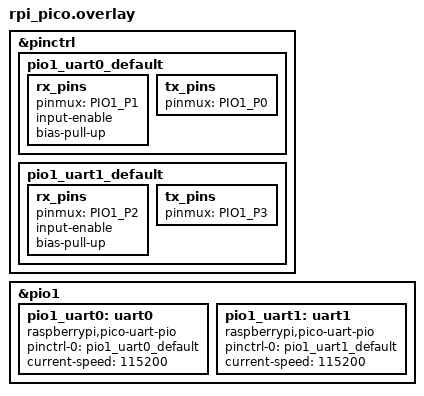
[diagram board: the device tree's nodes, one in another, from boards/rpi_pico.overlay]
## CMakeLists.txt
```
cmake_minimum_required(VERSION 3.15.0)
find_package(Zephyr REQUIRED HINTS $ENV{ZEPHYR_BASE})
project(pio_shell_uart)

target_sources(app PRIVATE src/main.c)
```

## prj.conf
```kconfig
CONFIG_LOG=y
CONFIG_SHELL=y
CONFIG_SERIAL=y
CONFIG_UART_INTERRUPT_DRIVEN=y
CONFIG_UART_CONSOLE=y
```

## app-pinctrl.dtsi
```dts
/*
 * Copyright (c) 2023, Ionut Pavel <iocapa@iocapa.com>
 * Copyright (c) 2023 Yonatan Schachter
 *
 * SPDX-License-Identifier: Apache-2.0
 */

#include <zephyr/dt-bindings/pinctrl/rpi-pico-rp2040-pinctrl.h>

&pinctrl {
	pio0_uart0_default: pio0_uart0_default {
		tx_gpio {
			pinmux = <PIO0_P0>;
		};

		rx_gpio {
			pinmux = <PIO0_P1>;
			input-enable;
			bias-pull-up;
		};
	};
};
```

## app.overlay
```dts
#include "app-pinctrl.dtsi"

/ {
	chosen {
		zephyr,console = &pio0_uart0;
		zephyr,shell-uart = &pio0_uart0;
	};
};

&uart0 {
	status = "disabled";
};

&pio0 {
	status = "okay";

	pio0_uart0: pio0_uart0 {
		compatible = "raspberrypi,pico-uart-pio";

		status = "okay";

		pio,interrupts = <0>;
		pio,interrupt-names = "shared";

		pinctrl-0 = <&pio0_uart0_default>;
		pinctrl-names = "default";

		current-speed = <115200>;
	};
};
```

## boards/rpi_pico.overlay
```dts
&pinctrl {
	pio1_uart0_default: pio1_uart0_default {
		rx_pins {
			pinmux = <PIO1_P1>;
			input-enable;
			bias-pull-up;
		};
		tx_pins {
			pinmux = <PIO1_P0>;
		};
	};

	pio1_uart1_default: pio1_uart1_default {
		rx_pins {
			pinmux = <PIO1_P2>;
			input-enable;
			bias-pull-up;
		};
		tx_pins {
			pinmux = <PIO1_P3>;
		};
	};
};

&pio1 {
 	status = "okay";

	pio1_uart0: uart0 {
		pinctrl-0 = <&pio1_uart0_default>;
		pinctrl-names = "default";

		compatible = "raspberrypi,pico-uart-pio";
		current-speed = <115200>;
		status = "okay";
	};

	pio1_uart1: uart1 {
		pinctrl-0 = <&pio1_uart1_default>;
		pinctrl-names = "default";

		compatible = "raspberrypi,pico-uart-pio";
		current-speed = <115200>;
		status = "okay";
	};
};
```

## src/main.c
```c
/*
 * Copyright (c) 2023 Yonatan Schachter
 *
 * SPDX-License-Identifier: Apache-2.0
 */

#include <zephyr/kernel.h>
#include <zephyr/device.h>
#include <zephyr/drivers/uart.h>

int main(void)
{
	char data;
	const struct device *uart0 = DEVICE_DT_GET(DT_NODELABEL(pio1_uart0));
	const struct device *uart1 = DEVICE_DT_GET(DT_NODELABEL(pio1_uart1));

	if (!device_is_ready(uart0)) {
		return 0;
	}

	if (!device_is_ready(uart1)) {
		return 0;
	}

	while (1) {
		if (!uart_poll_in(uart0, &data)) {
			(void)uart_poll_out(uart0, data);
		}

		if (!uart_poll_in(uart1, &data)) {
			(void)uart_poll_out(uart1, data);
		}
	}

	return 0;
}
```
